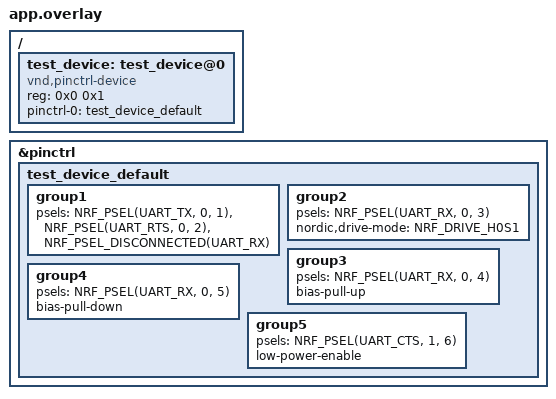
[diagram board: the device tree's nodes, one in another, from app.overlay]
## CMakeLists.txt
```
# Copyright (c) 2021 Nordic Semiconductor ASA
# SPDX-License-Identifier: Apache-2.0

cmake_minimum_required(VERSION 3.20.0)
find_package(Zephyr REQUIRED HINTS $ENV{ZEPHYR_BASE})

project(pinctrl_nrf)

target_sources(app PRIVATE src/main.c ../common/test_device.c)
```

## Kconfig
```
# Copyright (c) 2021 Nordic Semiconductor ASA
# SPDX-License-Identifier: Apache-2.0

mainmenu "pinctrl nRF DT Test"

source "Kconfig.zephyr"

config PINCTRL_TEST_NON_STATIC
	bool "Access to pin control configuration"
	select PINCTRL_NON_STATIC
	help
	  This option should be selected by unit tests that need to access the pin
	  control configuration defined in a device driver.
```

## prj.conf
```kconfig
CONFIG_ZTEST=y
CONFIG_PINCTRL_TEST_NON_STATIC=y
```

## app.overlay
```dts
/*
 * Copyright (c) 2021 Nordic Semiconductor ASA
 * SPDX-License-Identifier: Apache-2.0
 */

/ {
	test_device: test_device@0 {
		compatible = "vnd,pinctrl-device";
		reg = <0x0 0x1>;
		pinctrl-0 = <&test_device_default>;
		pinctrl-names = "default";
	};
};

&pinctrl {
	test_device_default: test_device_default {
		/* Note: the groups are just meant for testing if properties and
		   pins are parsed correctly, but do not necessarily represent a
		   feasible combination */
		group1 {
			psels = <NRF_PSEL(UART_TX, 0, 1)>,
				<NRF_PSEL(UART_RTS, 0, 2)>,
				<NRF_PSEL_DISCONNECTED(UART_RX)>;
		};
		group2 {
			psels = <NRF_PSEL(UART_RX, 0, 3)>;
			nordic,drive-mode = <NRF_DRIVE_H0S1>;
		};
		group3 {
			psels = <NRF_PSEL(UART_RX, 0, 4)>;
			bias-pull-up;
		};
		group4 {
			psels = <NRF_PSEL(UART_RX, 0, 5)>;
			bias-pull-down;
		};
		group5 {
			psels = <NRF_PSEL(UART_CTS, 1, 6)>;
			low-power-enable;
		};
	};
};
```

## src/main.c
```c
/*
 * Copyright (c) 2021 Nordic Semiconductor ASA
 *
 * SPDX-License-Identifier: Apache-2.0
 */

#include <zephyr/drivers/pinctrl.h>
#include <zephyr/ztest.h>

/* pin configuration for test device */
#define TEST_DEVICE DT_NODELABEL(test_device)
PINCTRL_DT_DEV_CONFIG_DECLARE(TEST_DEVICE);
static const struct pinctrl_dev_config *pcfg = PINCTRL_DT_DEV_CONFIG_GET(TEST_DEVICE);

ZTEST(pinctrl_nrf, test_dt_extract)
{
	const struct pinctrl_state *scfg;

	zassert_equal(pcfg->reg, 0x0U);
	zassert_equal(pcfg->state_cnt, 1U);

	scfg = &pcfg->states[0];

	zassert_equal(scfg->id, PINCTRL_STATE_DEFAULT);
	zassert_equal(scfg->pin_cnt, 7U);

	zassert_equal(NRF_GET_FUN(scfg->pins[0]), NRF_FUN_UART_TX);
	zassert_equal(NRF_GET_LP(scfg->pins[0]), NRF_LP_DISABLE);
	zassert_equal(NRF_GET_DRIVE(scfg->pins[0]), NRF_DRIVE_S0S1);
	zassert_equal(NRF_GET_PULL(scfg->pins[0]), NRF_PULL_NONE);
	zassert_equal(NRF_GET_PIN(scfg->pins[0]), 1U);

	zassert_equal(NRF_GET_FUN(scfg->pins[1]), NRF_FUN_UART_RTS);
	zassert_equal(NRF_GET_LP(scfg->pins[1]), NRF_LP_DISABLE);
	zassert_equal(NRF_GET_DRIVE(scfg->pins[1]), NRF_DRIVE_S0S1);
	zassert_equal(NRF_GET_PULL(scfg->pins[1]), NRF_PULL_NONE);
	zassert_equal(NRF_GET_PIN(scfg->pins[1]), 2U);

	zassert_equal(NRF_GET_FUN(scfg->pins[2]), NRF_FUN_UART_RX);
	zassert_equal(NRF_GET_PIN(scfg->pins[2]), NRF_PIN_DISCONNECTED);

	zassert_equal(NRF_GET_FUN(scfg->pins[3]), NRF_FUN_UART_RX);
	zassert_equal(NRF_GET_LP(scfg->pins[3]), NRF_LP_DISABLE);
	zassert_equal(NRF_GET_DRIVE(scfg->pins[3]), NRF_DRIVE_H0S1);
	zassert_equal(NRF_GET_PULL(scfg->pins[3]), NRF_PULL_NONE);
	zassert_equal(NRF_GET_PIN(scfg->pins[3]), 3U);

	zassert_equal(NRF_GET_FUN(scfg->pins[4]), NRF_FUN_UART_RX);
	zassert_equal(NRF_GET_LP(scfg->pins[4]), NRF_LP_DISABLE);
	zassert_equal(NRF_GET_DRIVE(scfg->pins[4]), NRF_DRIVE_S0S1);
	zassert_equal(NRF_GET_PULL(scfg->pins[4]), NRF_PULL_UP);
	zassert_equal(NRF_GET_PIN(scfg->pins[4]), 4U);

	zassert_equal(NRF_GET_FUN(scfg->pins[5]), NRF_FUN_UART_RX);
	zassert_equal(NRF_GET_LP(scfg->pins[5]), NRF_LP_DISABLE);
	zassert_equal(NRF_GET_DRIVE(scfg->pins[5]), NRF_DRIVE_S0S1);
	zassert_equal(NRF_GET_PULL(scfg->pins[5]), NRF_PULL_DOWN);
	zassert_equal(NRF_GET_PIN(scfg->pins[5]), 5U);

	zassert_equal(NRF_GET_FUN(scfg->pins[6]), NRF_FUN_UART_CTS);
	zassert_equal(NRF_GET_LP(scfg->pins[6]), NRF_LP_ENABLE);
	zassert_equal(NRF_GET_DRIVE(scfg->pins[6]), NRF_DRIVE_S0S1);
	zassert_equal(NRF_GET_PULL(scfg->pins[6]), NRF_PULL_NONE);
	zassert_equal(NRF_GET_PIN(scfg->pins[6]), 38U);
}

ZTEST_SUITE(pinctrl_nrf, NULL, NULL, NULL, NULL, NULL);
```
